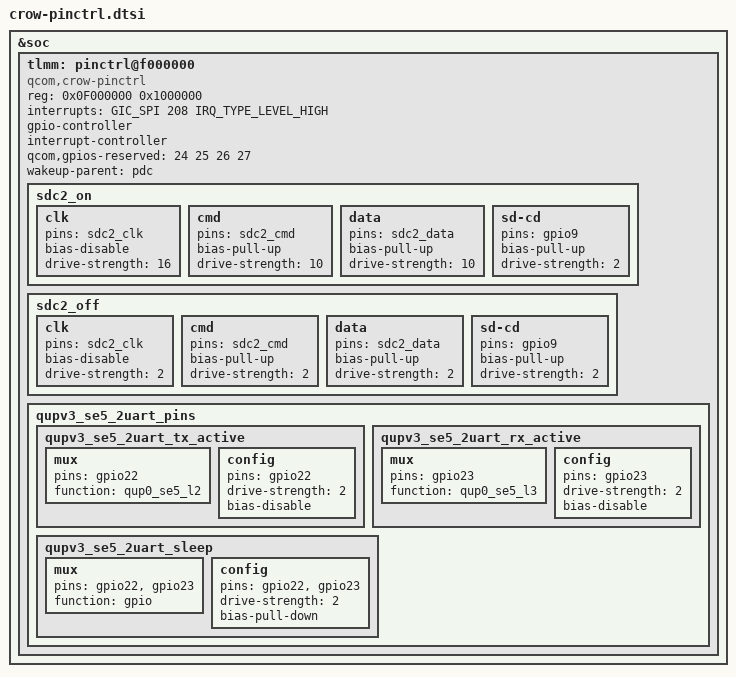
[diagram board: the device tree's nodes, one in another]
&soc {
	tlmm: pinctrl@f000000 {
		compatible = "qcom,crow-pinctrl";
		reg = <0x0F000000 0x1000000>;
		interrupts = <GIC_SPI 208 IRQ_TYPE_LEVEL_HIGH>;
		gpio-controller;
		#gpio-cells = <2>;
		interrupt-controller;
		#interrupt-cells = <2>;
		qcom,gpios-reserved = <24 25 26 27>;
		wakeup-parent = <&pdc>;

		sdc2_on: sdc2_on {
			clk {
				pins = "sdc2_clk";
				bias-disable;
				drive-strength = <16>;
			};

			cmd {
				pins = "sdc2_cmd";
				bias-pull-up;
				drive-strength = <10>;
			};

			data {
				pins = "sdc2_data";
				bias-pull-up;
				drive-strength = <10>;
			};

			sd-cd {
				pins = "gpio9";
				bias-pull-up;
				drive-strength = <2>;
			};
		};

		sdc2_off: sdc2_off {
			clk {
				pins = "sdc2_clk";
				bias-disable;
				drive-strength = <2>;
			};

			cmd {
				pins = "sdc2_cmd";
				bias-pull-up;
				drive-strength = <2>;
			};

			data {
				pins = "sdc2_data";
				bias-pull-up;
				drive-strength = <2>;
			};

			sd-cd {
				pins = "gpio9";
				bias-pull-up;
				drive-strength = <2>;
			};
		};
	};
};

&tlmm {
	qupv3_se5_2uart_pins: qupv3_se5_2uart_pins {
		qupv3_se5_2uart_tx_active: qupv3_se5_2uart_tx_active {
			mux {
				pins = "gpio22";
				function = "qup0_se5_l2";
			};

			config {
				pins = "gpio22";
				drive-strength = <2>;
				bias-disable;
			};
		};

		qupv3_se5_2uart_rx_active: qupv3_se5_2uart_rx_active {
			mux {
				pins = "gpio23";
				function = "qup0_se5_l3";
			};

			config {
				pins = "gpio23";
				drive-strength = <2>;
				bias-disable;
			};
		};

		qupv3_se5_2uart_sleep: qupv3_se5_2uart_sleep {
			mux {
				pins = "gpio22", "gpio23";
				function = "gpio";
			};

			config {
				pins = "gpio22", "gpio23";
				drive-strength = <2>;
				bias-pull-down;
			};
		};
	};
};
